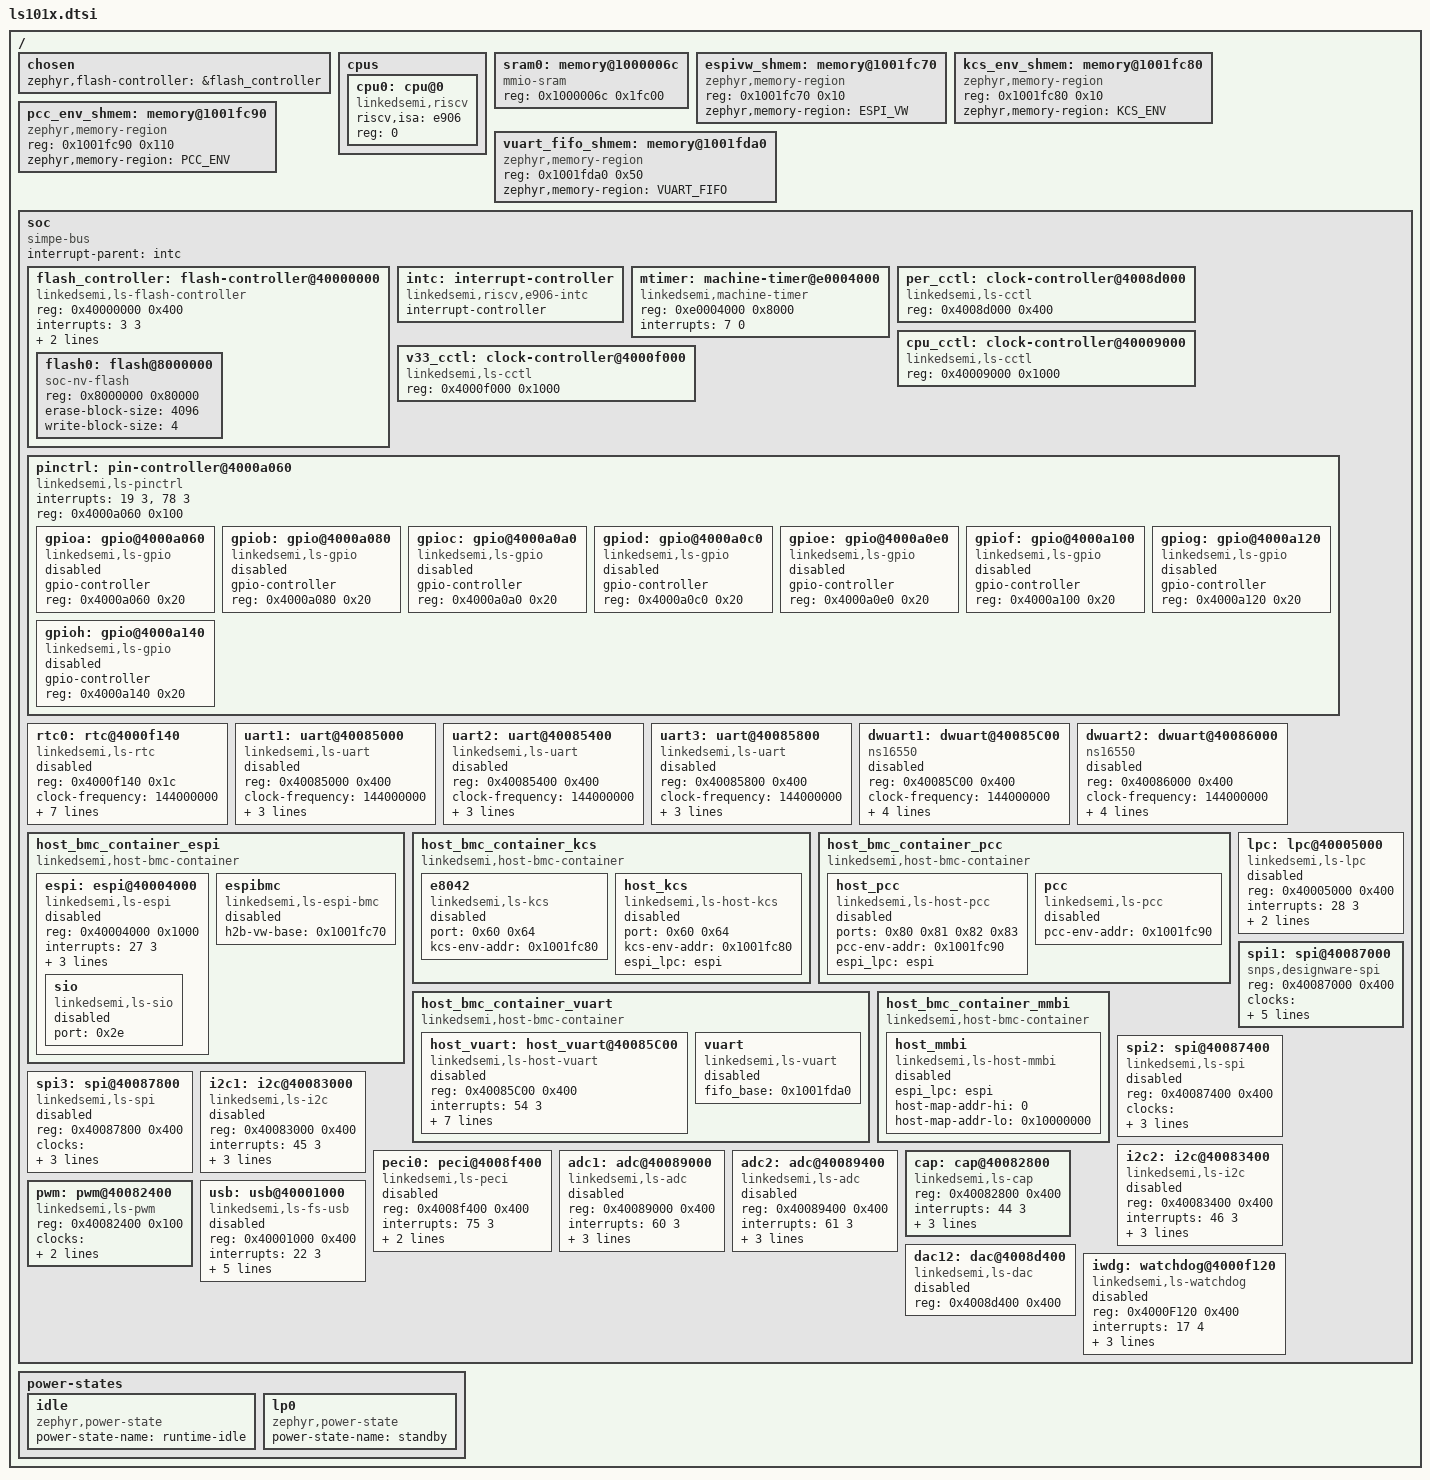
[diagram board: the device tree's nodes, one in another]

#include <zephyr/dt-bindings/gpio/gpio.h>
#include <zephyr/dt-bindings/clock/ls101x_clock.h>

/ {
    #address-cells = <1>;
    #size-cells = <1>;
    chosen {
		zephyr,flash-controller = &flash_controller;
	};

    cpus {
		#address-cells = <1>;
		#size-cells = <0>;
		cpu0: cpu@0 {
            device_type = "cpu";
            compatible = "linkedsemi,riscv";
            riscv,isa = "e906";
			reg = <0>;
		};
    };

    sram0: memory@1000006c{
        compatible = "mmio-sram";
        reg = <0x1000006c 0x1fc00>;
    };

    espivw_shmem: memory@1001fc70 {
        compatible = "zephyr,memory-region";
        reg = <0x1001fc70 0x10>;
        zephyr,memory-region = "ESPI_VW";
    };

    kcs_env_shmem: memory@1001fc80 {
        compatible = "zephyr,memory-region";
        reg = <0x1001fc80 0x10>;
        zephyr,memory-region = "KCS_ENV";
    };

    pcc_env_shmem: memory@1001fc90 {
        compatible = "zephyr,memory-region";
        reg = <0x1001fc90 0x110>;
        zephyr,memory-region = "PCC_ENV";
    };

    vuart_fifo_shmem: memory@1001fda0 {
        compatible = "zephyr,memory-region";
        reg = <0x1001fda0 0x50>;
        zephyr,memory-region = "VUART_FIFO";
    };

    soc {
        #address-cells = <1>;
        #size-cells = <1>;
        compatible = "simpe-bus";
        interrupt-parent = <&intc>;
        flash_controller: flash-controller@40000000 {
            compatible = "linkedsemi,ls-flash-controller";
            reg = <0x40000000 0x400>;

            #address-cells = <1>;
            #size-cells = <1>;
            interrupts = <3 3>;
            quad_mode;
            continuous_mode;

            flash0: flash@8000000 {
                compatible = "soc-nv-flash";
                reg = <0x8000000 0x80000>;
                erase-block-size = <4096>;
                write-block-size = <4>;
            };
        };
        intc: interrupt-controller {
            compatible = "linkedsemi,riscv,e906-intc";
            #address-cells = <0>;
            #interrupt-cells = <2>;
            interrupt-controller;
        };
        mtimer: machine-timer@e0004000 {
			compatible = "linkedsemi,machine-timer";
			reg = <0xe0004000 0x8000>;
			interrupts = <7 0>;
		};

        per_cctl: clock-controller@4008d000 {
            compatible = "linkedsemi,ls-cctl";
            #clock-cells = <3>;
            reg = <0x4008d000 0x400>;
            status = "okay";
        };

        cpu_cctl: clock-controller@40009000 {
            compatible = "linkedsemi,ls-cctl";
            #clock-cells = <3>;
            reg = <0x40009000 0x1000>;
            status = "okay";
        };
        v33_cctl: clock-controller@4000f000 {
            compatible = "linkedsemi,ls-cctl";
            #clock-cells = <3>;
            reg = <0x4000f000 0x1000>;
            status = "okay";
        };           

        pinctrl: pin-controller@4000a060 {
			compatible = "linkedsemi,ls-pinctrl";
			interrupts = <19 3>,<78 3>;
			interrupt-names = "EXTI_GPIO_V33","EXTI_GPIO_VCore";
            reg = <0x4000a060 0x100>;
			#address-cells = <1>;
			#size-cells = <1>;
            
			gpioa: gpio@4000a060 {
				compatible = "linkedsemi,ls-gpio";
				gpio-controller;
				#gpio-cells = <2>;
				reg = <0x4000a060 0x20>;
                status = "disabled";
			};

			gpiob: gpio@4000a080 {
				compatible = "linkedsemi,ls-gpio";
				gpio-controller;
				#gpio-cells = <2>;
				reg = <0x4000a080 0x20>;
                status = "disabled";
			};

			gpioc: gpio@4000a0a0 {
				compatible = "linkedsemi,ls-gpio";
				gpio-controller;
				#gpio-cells = <2>;
				reg = <0x4000a0a0 0x20>;
                status = "disabled";
			};

            gpiod: gpio@4000a0c0 {
				compatible = "linkedsemi,ls-gpio";
				gpio-controller;
				#gpio-cells = <2>;
				reg = <0x4000a0c0 0x20>;
                status = "disabled";
			};

            gpioe: gpio@4000a0e0 {
				compatible = "linkedsemi,ls-gpio";
				gpio-controller;
				#gpio-cells = <2>;
				reg = <0x4000a0e0 0x20>;
                status = "disabled";
			};

            gpiof: gpio@4000a100 {
				compatible = "linkedsemi,ls-gpio";
				gpio-controller;
				#gpio-cells = <2>;
				reg = <0x4000a100 0x20>;
                status = "disabled";
			};

            gpiog: gpio@4000a120 {
				compatible = "linkedsemi,ls-gpio";
				gpio-controller;
				#gpio-cells = <2>;
				reg = <0x4000a120 0x20>;
                status = "disabled";
			};

            gpioh: gpio@4000a140 {
				compatible = "linkedsemi,ls-gpio";
				gpio-controller;
				#gpio-cells = <2>;
				reg = <0x4000a140 0x20>;
                status = "disabled";
			};
        };
        rtc0: rtc@4000f140 {
            compatible = "linkedsemi,ls-rtc";
            reg = <0x4000f140 0x1c>;//地址手册定义7个数，28个字节
            clock-frequency = <144000000>; //CPU的主频是144000000Hz
            status = "disabled";//芯片层面dis
            //label = "RTC_LS101X";
		    interrupts = <16 3>;
		    interrupt-parent = <&intc>;
            clocks = <&v33_cctl LS_CCTL_CLKG4 LS_CLKG_SET_RTC_POS LS_CLKG_CLR_RTC_POS>;
            cyc-1hz = <32768>;     // 实际频率
            calib-cyc = <0>;          // 校准补偿周期数，单位是时钟周期
            calib-enable;             // 若存在此属性，则表示启用校准
        };
        uart1: uart@40085000 {
            compatible = "linkedsemi,ls-uart";
            reg = <0x40085000 0x400>;
            clock-frequency = <144000000>;
			status = "disabled";
            // label = "UART1";
            interrupts = <51 3> ;
            clocks = <&per_cctl LS_CCTL_CLKG1 LS_CLKG_SET_UART1_POS LS_CLKG_CLR_UART1_POS>;
        };
        uart2: uart@40085400 {
            compatible = "linkedsemi,ls-uart";
            reg = <0x40085400 0x400>;
            clock-frequency = <144000000>;
			status = "disabled";
            // label = "UART1";
            interrupts = <52 3> ;
            clocks = <&per_cctl LS_CCTL_CLKG1 LS_CLKG_SET_UART2_POS LS_CLKG_CLR_UART2_POS>;
        };
        uart3: uart@40085800 {
            compatible = "linkedsemi,ls-uart";
            reg = <0x40085800 0x400>;
            clock-frequency = <144000000>;
			status = "disabled";
            // label = "UART1";
            interrupts = <53 3> ;
            clocks = <&per_cctl LS_CCTL_CLKG1 LS_CLKG_SET_UART3_POS LS_CLKG_CLR_UART3_POS>;
        };

        dwuart1: dwuart@40085C00 {
            compatible = "ns16550","snps,dw-apb-uart";
            reg = <0x40085C00 0x400>;
			status = "disabled";
            clock-frequency = <144000000>;
            // label = "DWUART1";
            interrupts = <54 3> ;
            clocks = <&per_cctl LS_CCTL_CLKG1 LS_CLKG_SET_DWUART1_POS LS_CLKG_CLR_DWUART1_POS>;
			reg-shift = <2>;
        };
        
        dwuart2: dwuart@40086000 {
            compatible = "ns16550","snps,dw-apb-uart";
            reg = <0x40086000 0x400>;
			status = "disabled";
            clock-frequency = <144000000>;
            // label = "DWUART2";
            interrupts = <55 3> ;
            clocks = <&per_cctl LS_CCTL_CLKG1 LS_CLKG_SET_DWUART2_POS LS_CLKG_CLR_DWUART2_POS>;
            reg-shift = <2>;
        };

        host_bmc_container_espi: host_bmc_container_espi {
            compatible = "linkedsemi,host-bmc-container";
            #address-cells = <1>;
            #size-cells = <1>;
            status = "okay";

            espi: espi@40004000 {
                compatible = "linkedsemi,ls-espi";
                reg = <0x40004000 0x1000>;
                status = "disabled";
                interrupts = <27 3>;
                clocks = <&cpu_cctl LS_CCTL_CLKG LS_CLKG_SET_ESPI_POS LS_CLKG_CLR_ESPI_POS>;
                h2b-vw-base = <0x1001fc70>;

                sio: sio {
                    compatible = "linkedsemi,ls-sio";
                    port = <0x2e>;
                    status = "disabled";
                };
            };

            espibmc: espibmc {
                compatible = "linkedsemi,ls-espi-bmc";
                h2b-vw-base = <0x1001fc70>;
                status = "disabled";
            };
        };

        host_bmc_container_kcs: host_bmc_container_kcs {
            compatible = "linkedsemi,host-bmc-container";
            #address-cells = <1>;
            #size-cells = <1>;
            status = "okay";

            e8042: e8042 {
                compatible = "linkedsemi,ls-kcs";
                port = <0x60 0x64>;
                kcs-env-addr = <0x1001fc80>;
                status = "disabled";
            };

            host_kcs: host_kcs {
                compatible = "linkedsemi,ls-host-kcs";
                port = <0x60 0x64>;
                kcs-env-addr = <0x1001fc80>;
                espi_lpc = <&espi>;
                status = "disabled";
            };
        };

        host_bmc_container_pcc: host_bmc_container_pcc {
            compatible = "linkedsemi,host-bmc-container";
            #address-cells = <1>;
            #size-cells = <1>;
            status = "okay";

            host_pcc: host_pcc {
                compatible = "linkedsemi,ls-host-pcc";
                ports = <0x80 0x81 0x82 0x83>;
                pcc-env-addr = <0x1001fc90>;
                espi_lpc = <&espi>;
                status = "disabled";
            };

            pcc: pcc {
                compatible = "linkedsemi,ls-pcc";
                pcc-env-addr = <0x1001fc90>;
                status = "disabled";
            };
        };

        host_bmc_container_vuart: host_bmc_container_vuart {
            compatible = "linkedsemi,host-bmc-container";
            #address-cells = <1>;
            #size-cells = <1>;
            status = "okay";

            host_vuart: host_vuart@40085C00 {
                compatible = "linkedsemi,ls-host-vuart";
                reg = <0x40085C00 0x400>;
                interrupts = <54 3>;
                port = <0x3f8>;
                clock-source = <CLK_SRC_PBUS4>;
                up-irq = <0x4 0>;
                fifo_base = <0x1001fda0>;
                espi_lpc = <&espi>;
                clocks = <&per_cctl LS_CCTL_CLKG1 LS_CLKG_SET_DWUART1_POS LS_CLKG_CLR_DWUART1_POS>;
                status = "disabled";
            };

            vuart: vuart {
                compatible = "linkedsemi,ls-vuart";
                fifo_base = <0x1001fda0>;
                status = "disabled";
            };
        };

        host_bmc_container_mmbi: host_bmc_container_mmbi {
            compatible = "linkedsemi,host-bmc-container";
            #address-cells = <1>;
            #size-cells = <1>;
            status = "okay";

            host_mmbi: host_mmbi {
                compatible = "linkedsemi,ls-host-mmbi";
                espi_lpc = <&espi>;
                host-map-addr-hi = <0>;
                host-map-addr-lo = <0x10000000>;
                status = "disabled";
            };
        };
        lpc: lpc@40005000 {
            compatible = "linkedsemi,ls-lpc";
            reg = <0x40005000 0x400>;
            status = "disabled";
            interrupts = <28 3>;
            clocks = <&cpu_cctl LS_CCTL_CLKG LS_CLKG_SET_LPC_POS LS_CLKG_CLR_LPC_POS>;
        };
		spi1: spi@40087000 {
			compatible = "snps,designware-spi";
			#address-cells = <1>;
			#size-cells = <0>;
			reg = <0x40087000 0x400>;
            clocks = <&per_cctl LS_CCTL_CLKG1 LS_CLKG_SET_SPI1_POS LS_CLKG_CLR_SPI1_POS>;
			fifo-depth = <4>;
			interrupts = <56 3>;
			clock-frequency = <144000000>;
            max-xfer-size = <32>;
			status = "okay";
		};

        spi2: spi@40087400 {
            compatible = "linkedsemi,ls-spi";
            #address-cells = <1>;
			#size-cells = <0>;
			reg = <0x40087400 0x400>;
            clocks = <&per_cctl LS_CCTL_CLKG1 LS_CLKG_SET_SPI2_POS LS_CLKG_CLR_SPI2_POS>;
			interrupts = <57 3>;
            clock-frequency = <144000000>;
			status = "disabled";
        };

        
        spi3: spi@40087800 {
            compatible = "linkedsemi,ls-spi";
            #address-cells = <1>;
			#size-cells = <0>;
			reg = <0x40087800 0x400>;
            clocks = <&per_cctl LS_CCTL_CLKG1 LS_CLKG_SET_SPI3_POS LS_CLKG_CLR_SPI3_POS>;
			interrupts = <58 3>;
            clock-frequency = <144000000>;
			status = "disabled";
        };

        i2c1: i2c@40083000 {
            compatible = "linkedsemi,ls-i2c";
            reg = <0x40083000 0x400>;
            #address-cells = <1>;
			#size-cells = <0>;
            interrupts = <45 3>;
            clocks = <&per_cctl LS_CCTL_CLKG0 LS_CLKG_SET_I2C1_POS LS_CLKG_CLR_I2C1_POS>;
            clock-frequency = <144000000>;
            status = "disabled";
        };

        i2c2: i2c@40083400 {
            compatible = "linkedsemi,ls-i2c";
            reg = <0x40083400 0x400>;
            #address-cells = <1>;
			#size-cells = <0>;
            interrupts = <46 3>;
            clocks = <&per_cctl LS_CCTL_CLKG0 LS_CLKG_SET_I2C2_POS LS_CLKG_CLR_I2C2_POS>;
            clock-frequency = <144000000>;
            status = "disabled";
        };

		peci0: peci@4008f400 {
			compatible = "linkedsemi,ls-peci";
			reg = <0x4008f400 0x400>;
			#address-cells= <1>;
			#size-cells = <0>;
			interrupts = <75 3>;
            clocks = <&per_cctl LS_CCTL_CLKG3 LS_CLKG_SET_PECI_POS LS_CLKG_CLR_PECI_POS>;
			status = "disabled";
		};


        adc1: adc@40089000 {
            compatible = "linkedsemi,ls-adc";
            reg = <0x40089000 0x400>;
            status = "disabled";
            // lable = "ADC1";
            interrupts = <60 3>;
          	clocks = <&per_cctl LS_CCTL_CLKG2 LS_CLKG_SET_ADC1_POS LS_CLKG_CLR_ADC1_POS>;
            clock-source = <CLK_SRC_PBUS4>;
            #hwmon-in-cells = <1>;
        };

        adc2: adc@40089400 {
            compatible = "linkedsemi,ls-adc";
            reg = <0x40089400 0x400>;
            status = "disabled";
            // lable = "ADC2";
            interrupts = <61 3>;
          	clocks = <&per_cctl LS_CCTL_CLKG2 LS_CLKG_SET_ADC2_POS LS_CLKG_CLR_ADC2_POS>;
            clock-source = <CLK_SRC_PBUS4>;
        };

        cap:cap@40082800 {
            compatible = "linkedsemi,ls-cap";
            reg = <0x40082800 0x400>;
            status = "okay";
            interrupts = <44 3>;  
          	clocks = <&per_cctl LS_CCTL_CLKG0 LS_CLKG_SET_CAP_POS LS_CLKG_CLR_CAP_POS>;
            clock-frequency = <144000000>;
            #hwmon-in-cells = <1>;
          };
          
        pwm:pwm@40082400 {
            compatible = "linkedsemi,ls-pwm";
            reg = <0x40082400 0x100>;
            status = "okay";
            clocks = <&per_cctl LS_CCTL_CLKG0 LS_CLKG_SET_PWM_POS LS_CLKG_CLR_PWM_POS>;
            clock-frequency = <144000000>;
            #hwmon-out-cells = <1>;
            #pwm-cells = <3>;
        };

        dac12: dac@4008d400 {
            compatible = "linkedsemi,ls-dac";
            reg = <0x4008d400 0x400>;
            status = "disabled";
            // lable = "DAC12"
        };

        usb: usb@40001000 {
            compatible = "linkedsemi,ls-fs-usb";
            reg = <0x40001000 0x400>;
            interrupts = <22 3>;
            num-bidir-endpoints = <8>;
            maximum-speed = "full-speed";
            ram-size = <64>;
            clocks = <&cpu_cctl LS_CCTL_CLKG LS_CLKG_SET_USB_POS LS_CLKG_CLR_USB_POS>;
            status = "disabled";
        };

        iwdg:watchdog@4000f120 {
          compatible = "linkedsemi,ls-watchdog";
          reg = <0x4000F120 0x400>;
          interrupts = <17 4>;
          status = "disabled";
        	clocks = <&v33_cctl LS_CCTL_CLKG4 LS_CLKG_SET_WDT_MASK LS_CLKG_CLR_WDT_MASK>;
          clock-frequency = <32768>;
        };
  
    };
    power-states {
        idle: idle{
            compatible = "zephyr,power-state";
			power-state-name = "runtime-idle";
        };
        
        lp0: lp0 {
			compatible = "zephyr,power-state";
			power-state-name = "standby";
        };
    };
};
